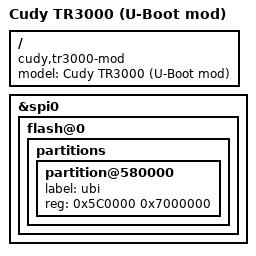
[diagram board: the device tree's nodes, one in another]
// SPDX-License-Identifier: GPL-2.0-or-later OR MIT

/dts-v1/;
#include "mt7981b-cudy-tr3000-v1.dts"

/ {
	model = "Cudy TR3000 (U-Boot mod)";
	compatible = "cudy,tr3000-mod", "mediatek,mt7981-spim-snand-rfb";
};

&spi0 {
	flash@0 {
		partitions {
			partition@580000 {
				label = "ubi";
				reg = <0x5C0000 0x7000000>;
			};
		};
	};
};
